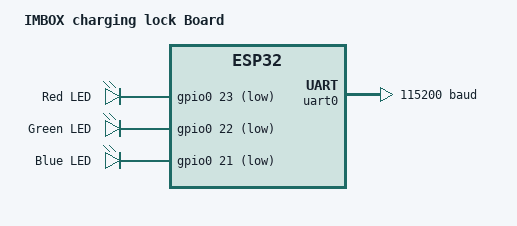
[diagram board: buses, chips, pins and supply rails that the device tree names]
/*
 * SPDX-License-Identifier: Apache-2.0
 */
/dts-v1/;

#include <espressif/esp32/esp32_wrover_e_n4r8.dtsi>
#include "imbox-pinctrl.dtsi"
#include <espressif/partitions_0x1000_amp.dtsi>

/ {
	model = "IMBOX charging lock Board";
	compatible = "imbox_org,imbox";

	aliases {
		uart-0 = &uart0;
		led0 = &ledred;
		led1 = &ledgreen;
		led2 = &ledblue;
		/* app-led maps to the red LED; main.cpp uses DT_ALIAS(app_led) */
		app-led = &ledred;
	};

	chosen {
		zephyr,sram = &sram1;
		zephyr,console = &uart0;
		zephyr,shell-uart = &uart0;
		zephyr,flash = &flash0;
		zephyr,code-partition = &slot0_partition;
		zephyr,bt-hci = &esp32_bt_hci;
	};

	leds {
		compatible = "gpio-leds";

		ledred: led_23 {
			gpios = <&gpio0 23 GPIO_ACTIVE_LOW>;
			label = "Red LED";
		};

		ledgreen: led_22 {
			gpios = <&gpio0 22 GPIO_ACTIVE_LOW>;
			label = "Green LED";
		};

		ledblue: led_21 {
			gpios = <&gpio0 21 GPIO_ACTIVE_LOW>;
			label = "Blue LED";
		};
	};
};

&uart0 {
	status = "okay";
	current-speed = <115200>;
	pinctrl-0 = <&uart0_default>;
	pinctrl-names = "default";
};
